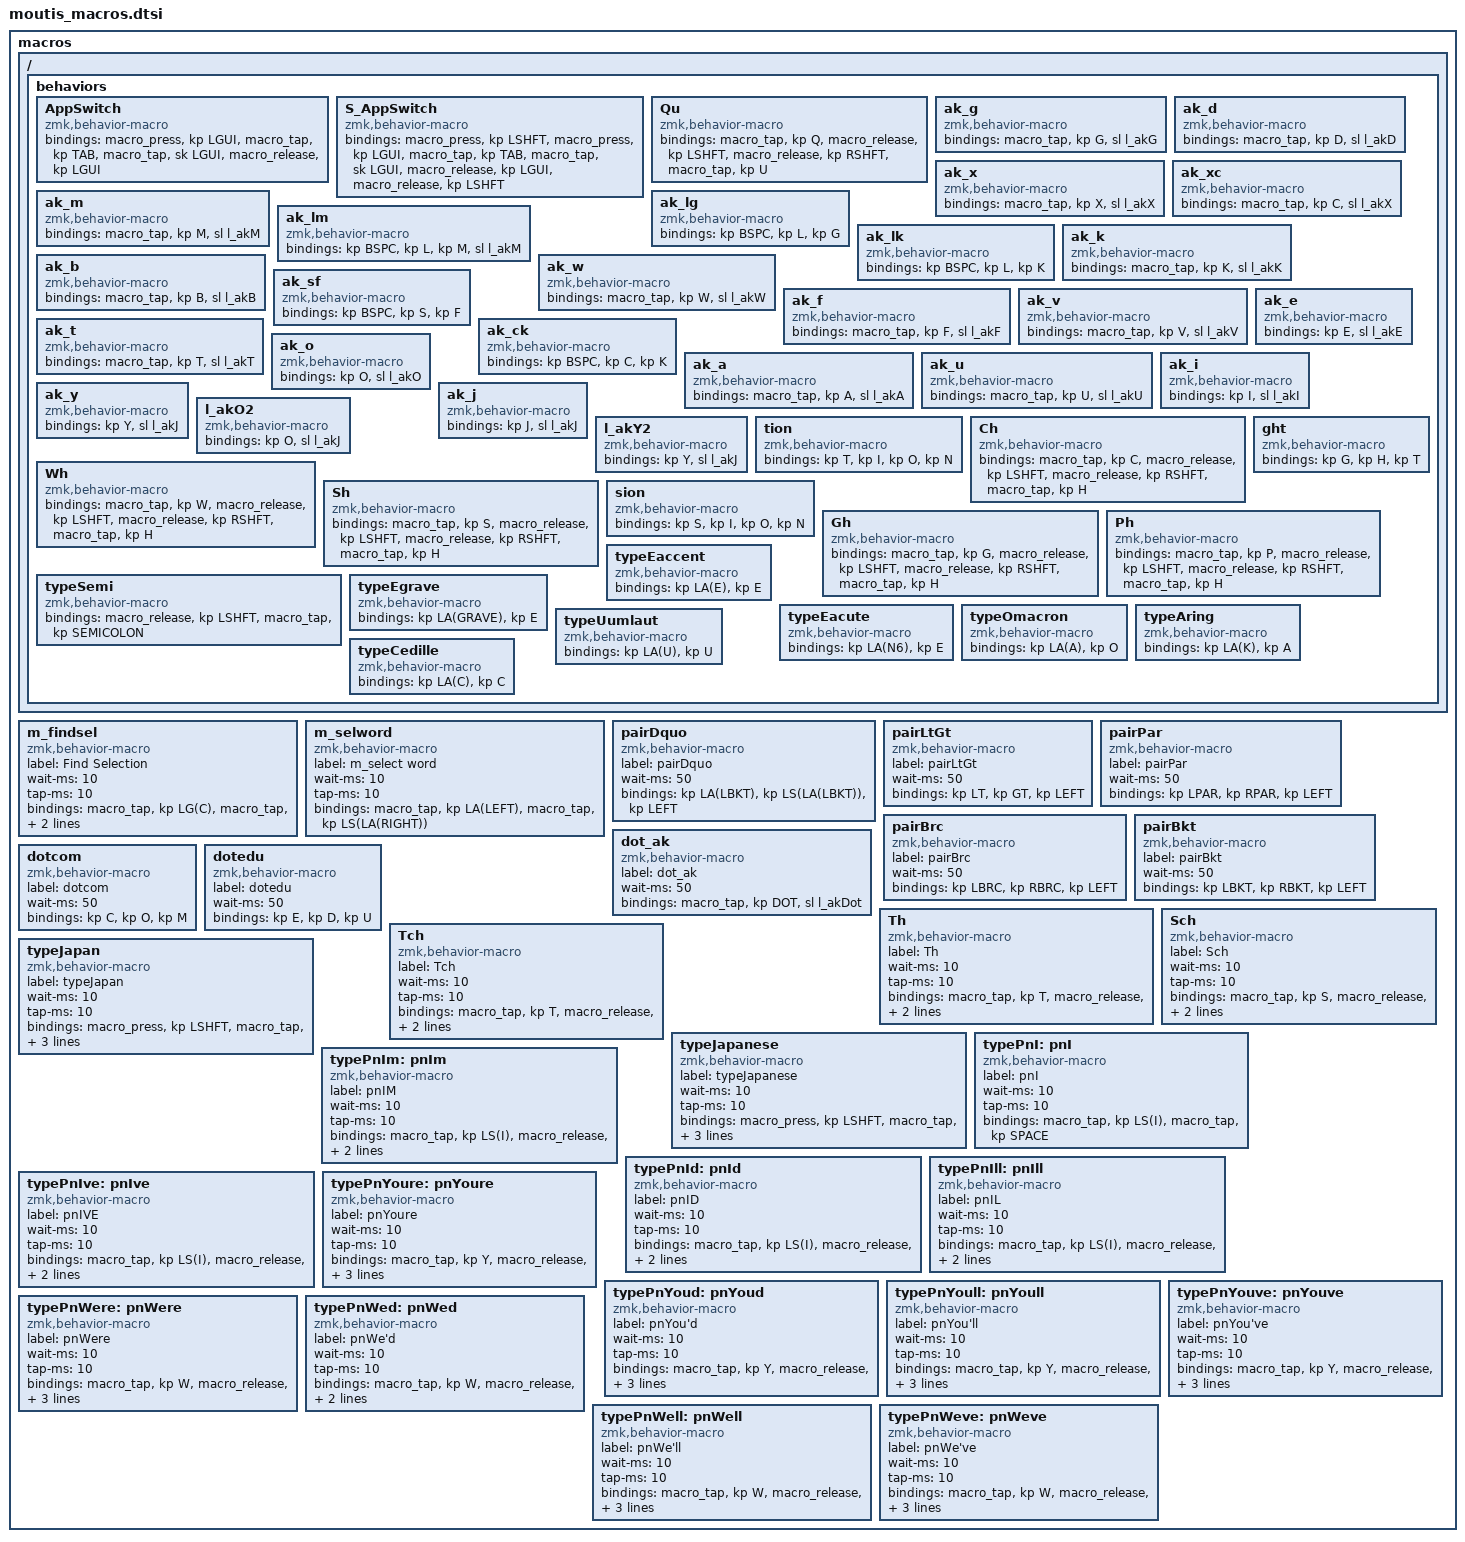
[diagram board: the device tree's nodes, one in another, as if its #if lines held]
 

    macros {

    ZMK_MACRO(AppSwitch,
        bindings =  <&macro_press &kp LGUI> // leave GUI down to keep menu up
                , <&macro_tap &kp TAB> // combines with shift fine
                , <&macro_tap &sk LGUI> // this will release GUI after a timeout
                , <&macro_release &kp LGUI> // now release the previous hold
                        ;
        )

    ZMK_MACRO(S_AppSwitch,
        bindings =  <&macro_press &kp LSHFT> //
                , <&macro_press &kp LGUI> // leave GUI down to keep menu up
                , <&macro_tap &kp TAB> // combines with shift fine
                , <&macro_tap &sk LGUI> // this will release GUI after a timeout
                , <&macro_release &kp LGUI> // now release the previous hold
                , <&macro_release &kp LSHFT> //
                        ;
        )


        m_findsel: m_findsel {
            label = "Find Selection";
            compatible = "zmk,behavior-macro";
            #binding-cells = <0>;
            wait-ms = <10>;
            tap-ms = <10>;
             bindings = <&macro_tap &kp LG(C)>
                    , <&macro_tap &kp LG(F)>
                    , <&macro_tap &kp LG(V)>
                    , <&macro_tap &kp RETURN>
                    , <&macro_tap &kp LG(G)>
                ;
        };

        m_selword: m_selword {
            label = "m_select word";
            compatible = "zmk,behavior-macro";
            #binding-cells = <0>;
            wait-ms = <10>;
            tap-ms = <10>;
            bindings = <&macro_tap &kp LA(LEFT)>
                    , <&macro_tap &kp LS(LA(RIGHT))>
                ;
        };


    ZMK_MACRO(Qu,
        bindings = <&macro_tap &kp Q>
                , <&macro_release &kp LSHFT>
                , <&macro_release &kp RSHFT>
                , <&macro_tap &kp U>
                ;
        )

    pairDquo: pairDquo {
        label = "pairDquo";
        compatible = "zmk,behavior-macro";
        #binding-cells = <0>;
        wait-ms = <50>; // need to slow this down for some systems.
        bindings = <&kp LA(LBKT) &kp LS(LA(LBKT)) &kp LEFT>
                ;
        };
    pairLtGt: pairLtGt {
        label = "pairLtGt";
        compatible = "zmk,behavior-macro";
        #binding-cells = <0>;
        wait-ms = <50>; // need to slow this down for some systems.
        bindings = <&kp LT &kp GT &kp LEFT>
                ;
        };
    pairPar: pairPar {
        label = "pairPar";
        compatible = "zmk,behavior-macro";
        #binding-cells = <0>;
        wait-ms = <50>; // need to slow this down for some systems.
        bindings = <&kp LPAR &kp RPAR &kp LEFT>
                ;
        };
    pairBrc: pairBrc {
        label = "pairBrc";
        compatible = "zmk,behavior-macro";
        #binding-cells = <0>;
        wait-ms = <50>; // need to slow this down for some systems.
        bindings = <&kp LBRC &kp RBRC &kp LEFT>
                ;
        };
    pairBkt: pairBkt {
        label = "pairBkt";
        compatible = "zmk,behavior-macro";
        #binding-cells = <0>;
        wait-ms = <50>; // need to slow this down for some systems.
        bindings = <&kp LBKT &kp RBKT &kp LEFT>
                ;
        };
    dot_ak: dot_ak {
        label = "dot_ak";
        compatible = "zmk,behavior-macro";
        #binding-cells = <0>;
        wait-ms = <50>; // need to slow this down for some systems.
        bindings = <&macro_tap &kp DOT>
                , <&sl l_akDot>;
        };
    dotcom: dotcom {
        label = "dotcom";
        compatible = "zmk,behavior-macro";
        #binding-cells = <0>;
        wait-ms = <50>; // need to slow this down for some systems.
        bindings = <&kp C &kp O &kp M>
                ;
        };
    dotedu: dotedu {
        label = "dotedu";
        compatible = "zmk,behavior-macro";
        #binding-cells = <0>;
        wait-ms = <50>; // need to slow this down for some systems.
        bindings = <&kp E &kp D &kp U>
                ;
        };

    ZMK_MACRO(ak_g,
        bindings = <&macro_tap &kp G>
                , <&sl l_akG>;
        )
    ZMK_MACRO(ak_d,
        bindings = <&macro_tap &kp D>
                , <&sl l_akD>;
        )
    ZMK_MACRO(ak_x,
        bindings = <&macro_tap &kp X>
                , <&sl l_akX>;
        )
    ZMK_MACRO(ak_xc,
        bindings = <&macro_tap &kp C>
                , <&sl l_akX>;
        )
    ZMK_MACRO(ak_m,
        bindings = <&macro_tap &kp M>
                , <&sl l_akM>;
        )
    ZMK_MACRO(ak_lg,
        bindings = <&kp BSPC &kp L &kp G>;
        )
    ZMK_MACRO(ak_lm,
        bindings = <&kp BSPC &kp L &kp M>
                    , <&sl l_akM>
        ;
        )
    ZMK_MACRO(ak_lk,
        bindings = <&kp BSPC &kp L &kp K>;
        )
    ZMK_MACRO(ak_k,
        bindings = <&macro_tap &kp K>
                , <&sl l_akK>;
        )
    ZMK_MACRO(ak_w,
        bindings = <&macro_tap &kp W>
                , <&sl l_akW>;
        )
    ZMK_MACRO(ak_b,
        bindings = <&macro_tap &kp B>
                , <&sl l_akB>;
        )
    ZMK_MACRO(ak_sf,
        bindings = <&kp BSPC &kp S &kp F>;
        )
    ZMK_MACRO(ak_f,
        bindings = <&macro_tap &kp F>
                , <&sl l_akF>;
        )
    ZMK_MACRO(ak_v,
        bindings = <&macro_tap &kp V>
                , <&sl l_akV>;
        )

    ZMK_MACRO(ak_t,
        bindings = <&macro_tap &kp T>
                , <&sl l_akT>;
        )
    ZMK_MACRO(ak_ck,
        bindings = <&kp BSPC &kp C &kp K>;
        )
    ZMK_MACRO(ak_a,
        bindings = <&macro_tap &kp A>
                , <&sl l_akA>;
        )
    ZMK_MACRO(ak_u,
        bindings = <&macro_tap &kp U>
                , <&sl l_akU>;
        )
    ZMK_MACRO(ak_e,
        bindings = <&kp E &sl l_akE>;
        )
    ZMK_MACRO(ak_o,
        bindings = <&kp O &sl l_akO>;
        )
    ZMK_MACRO(ak_i,
        bindings = <&kp I &sl l_akI>;
        )
    ZMK_MACRO(ak_y,
        bindings = <&kp Y &sl l_akJ>;
        )
    ZMK_MACRO(ak_j,
        bindings = <&kp J &sl l_akJ>;
        )
    ZMK_MACRO(l_akO2,
        bindings = <&kp O &sl l_akJ>;
        )
    ZMK_MACRO(l_akY2,
        bindings = <&kp Y &sl l_akJ>;
        )




    Th: Th {
        label = "Th";
        compatible = "zmk,behavior-macro";
        #binding-cells = <0>;
        wait-ms = <10>;
        tap-ms = <10>;
        bindings = <&macro_tap &kp T>
            , <&macro_release &kp LSHFT>
            , <&macro_release &kp RSHFT>
            , <&macro_tap &kp H>
            ;
        };
    ZMK_MACRO(tion,
        bindings = <&kp T &kp I &kp O &kp N>
                ;
        )
    ZMK_MACRO(Ch,
        bindings = <&macro_tap &kp C>
                , <&macro_release &kp LSHFT>
                , <&macro_release &kp RSHFT>
                , <&macro_tap &kp H>
                ;
        )
    ZMK_MACRO(Wh,
        bindings = <&macro_tap &kp W>
                , <&macro_release &kp LSHFT>
                , <&macro_release &kp RSHFT>
                , <&macro_tap &kp H>
                ;
        )
    ZMK_MACRO(Sh,
        bindings = <&macro_tap &kp S>
                , <&macro_release &kp LSHFT>
                , <&macro_release &kp RSHFT>
                , <&macro_tap &kp H>
                ;
        )
    ZMK_MACRO(sion,
        bindings = <&kp S &kp I &kp O &kp N>
                ;
        )
    ZMK_MACRO(Gh,
        bindings = <&macro_tap &kp G>
                , <&macro_release &kp LSHFT>
                , <&macro_release &kp RSHFT>
                , <&macro_tap &kp H>
                ;
        )
    ZMK_MACRO(ght,
        bindings = <&kp G &kp H &kp T>
                ;
        )
    ZMK_MACRO(Ph,
        bindings = <&macro_tap &kp P>
                , <&macro_release &kp LSHFT>
                , <&macro_release &kp RSHFT>
                , <&macro_tap &kp H>
                ;
        )


        Sch: Sch {
            label = "Sch";
            compatible = "zmk,behavior-macro";
            #binding-cells = <0>;
            wait-ms = <10>;
            tap-ms = <10>;
            bindings = <&macro_tap &kp S>
                    , <&macro_release &kp LSHFT>
                    , <&macro_release &kp RSHFT>
                    , <&macro_tap &kp C &kp H>
                ;
        };
        Tch: Tch {
            label = "Tch";
            compatible = "zmk,behavior-macro";
            #binding-cells = <0>;
            wait-ms = <10>;
            tap-ms = <10>;
            bindings = <&macro_tap &kp T>
                    , <&macro_release &kp LSHFT>
                    , <&macro_release &kp RSHFT>
                    , <&macro_tap &kp C &kp H>
                ;
        };

    ZMK_MACRO(typeSemi,
        bindings = <&macro_release &kp LSHFT>
                , <&macro_tap &kp SEMICOLON>
                ;
        )
    ZMK_MACRO(typeEaccent,
        bindings = <&kp LA(E) &kp E>
                ;
        )
    ZMK_MACRO(typeEgrave,
        bindings = <&kp LA(GRAVE) &kp E>
                ;
        )
    ZMK_MACRO(typeEacute,
        bindings = <&kp LA(N6) &kp E>
                ;
        )
    ZMK_MACRO(typeOmacron,
        bindings = <&kp LA(A) &kp O>
                ;
        )
    ZMK_MACRO(typeAring,
        bindings = <&kp LA(K) &kp A>
                ;
        )
    ZMK_MACRO(typeUumlaut,
        bindings = <&kp LA(U) &kp U>
                ;
        )
    ZMK_MACRO(typeCedille,
        bindings = <&kp LA(C) &kp C>
                ;
        )
        typeJapan: typeJapan {
            label = "typeJapan";
            compatible = "zmk,behavior-macro";
            #binding-cells = <0>;
            wait-ms = <10>;
            tap-ms = <10>;
            bindings = <&macro_press &kp LSHFT>
                    , <&macro_tap &kp J>
                    , <&macro_release &kp LSHFT>
                    , <&macro_release &kp RSHFT>
                    , <&macro_tap &kp A &kp P &kp A &kp N &kp SPACE>
                ;
        };
        typeJapanese: typeJapanese {
            label = "typeJapanese";
            compatible = "zmk,behavior-macro";
            #binding-cells = <0>;
            wait-ms = <10>;
            tap-ms = <10>;
            bindings = <&macro_press &kp LSHFT>
                    , <&macro_tap &kp J>
                    , <&macro_release &kp LSHFT>
                    , <&macro_release &kp RSHFT>
                    , <&macro_tap &kp A &kp P &kp A &kp N &kp E &kp S &kp E &kp SPACE>
                ;
        };


#ifdef EN_PRONOUN_COMBOS
// Pronouns
        typePnI: pnI {
            label = "pnI";
            compatible = "zmk,behavior-macro";
            #binding-cells = <0>;
            wait-ms = <10>;
            tap-ms = <10>;
            bindings = <&macro_tap &kp LS(I)>
                    , <&macro_tap &kp SPACE>
                ;
        };
        typePnIm: pnIm {
            label = "pnIM";
            compatible = "zmk,behavior-macro";
            #binding-cells = <0>;
            wait-ms = <10>;
            tap-ms = <10>;
            bindings = <&macro_tap &kp LS(I)>
                    , <&macro_release &kp LSHFT>
                    , <&macro_release &kp RSHFT>
                    , <&macro_tap &kp APOS &kp M &kp SPACE>
                ;
        };
        typePnId: pnId {
            label = "pnID";
            compatible = "zmk,behavior-macro";
            #binding-cells = <0>;
            wait-ms = <10>;
            tap-ms = <10>;
            bindings = <&macro_tap &kp LS(I)>
                    , <&macro_release &kp LSHFT>
                    , <&macro_release &kp RSHFT>
                    , <&macro_tap &kp APOS &kp D &kp SPACE>
                ;
        };
        typePnIll: pnIll {
            label = "pnIL";
            compatible = "zmk,behavior-macro";
            #binding-cells = <0>;
            wait-ms = <10>;
            tap-ms = <10>;
            bindings = <&macro_tap &kp LS(I)>
                    , <&macro_release &kp LSHFT>
                    , <&macro_release &kp RSHFT>
                    , <&macro_tap &kp APOS &kp L &kp L &kp SPACE>
                ;
        };
        typePnIve: pnIve {
            label = "pnIVE";
            compatible = "zmk,behavior-macro";
            #binding-cells = <0>;
            wait-ms = <10>;
            tap-ms = <10>;
            bindings = <&macro_tap &kp LS(I)>
                    , <&macro_release &kp LSHFT>
                    , <&macro_release &kp RSHFT>
                    , <&macro_tap &kp APOS &kp V &kp E &kp SPACE>
                ;
        };
// YOU
        typePnYoure: pnYoure {
            label = "pnYoure";
            compatible = "zmk,behavior-macro";
            #binding-cells = <0>;
            wait-ms = <10>;
            tap-ms = <10>;
            bindings = <&macro_tap &kp Y>
                    , <&macro_release &kp LSHFT>
                    , <&macro_release &kp RSHFT>
                    , <&macro_tap &kp O &kp U &kp APOS &kp R &kp E &kp SPACE>
                ;
        };
        typePnYoud: pnYoud {
            label = "pnYou'd";
            compatible = "zmk,behavior-macro";
            #binding-cells = <0>;
            wait-ms = <10>;
            tap-ms = <10>;
            bindings = <&macro_tap &kp Y>
                    , <&macro_release &kp LSHFT>
                    , <&macro_release &kp RSHFT>
                    , <&macro_tap &kp O &kp U &kp APOS &kp D &kp SPACE>
                ;
        };
        typePnYoull: pnYoull {
            label = "pnYou'll";
            compatible = "zmk,behavior-macro";
            #binding-cells = <0>;
            wait-ms = <10>;
            tap-ms = <10>;
            bindings = <&macro_tap &kp Y>
                    , <&macro_release &kp LSHFT>
                    , <&macro_release &kp RSHFT>
                    , <&macro_tap &kp O &kp U &kp APOS &kp L &kp L &kp SPACE>
                ;
        };
        typePnYouve: pnYouve {
            label = "pnYou've";
            compatible = "zmk,behavior-macro";
            #binding-cells = <0>;
            wait-ms = <10>;
            tap-ms = <10>;
            bindings = <&macro_tap &kp Y>
                    , <&macro_release &kp LSHFT>
                    , <&macro_release &kp RSHFT>
                    , <&macro_tap &kp O &kp U &kp APOS &kp V &kp E &kp SPACE>
                ;
        };
// WE
        typePnWere: pnWere {
            label = "pnWere";
            compatible = "zmk,behavior-macro";
            #binding-cells = <0>;
            wait-ms = <10>;
            tap-ms = <10>;
            bindings = <&macro_tap &kp W>
                    , <&macro_release &kp LSHFT>
                    , <&macro_release &kp RSHFT>
                    , <&macro_tap &kp E &kp APOS &kp R &kp E &kp SPACE>
                ;
        };
        typePnWed: pnWed {
            label = "pnWe'd";
            compatible = "zmk,behavior-macro";
            #binding-cells = <0>;
            wait-ms = <10>;
            tap-ms = <10>;
            bindings = <&macro_tap &kp W>
                    , <&macro_release &kp LSHFT>
                    , <&macro_release &kp RSHFT>
                    , <&macro_tap &kp E &kp APOS &kp D &kp SPACE>
                ;
        };
        typePnWell: pnWell {
            label = "pnWe'll";
            compatible = "zmk,behavior-macro";
            #binding-cells = <0>;
            wait-ms = <10>;
            tap-ms = <10>;
            bindings = <&macro_tap &kp W>
                    , <&macro_release &kp LSHFT>
                    , <&macro_release &kp RSHFT>
                    , <&macro_tap &kp E &kp APOS &kp L &kp L &kp SPACE>
                ;
        };
        typePnWeve: pnWeve {
            label = "pnWe've";
            compatible = "zmk,behavior-macro";
            #binding-cells = <0>;
            wait-ms = <10>;
            tap-ms = <10>;
            bindings = <&macro_tap &kp W>
                    , <&macro_release &kp LSHFT>
                    , <&macro_release &kp RSHFT>
                    , <&macro_tap &kp E &kp APOS &kp V &kp E &kp SPACE>
                ;
        };

#endif // EN_PRONOUN_COMBOS

    };

